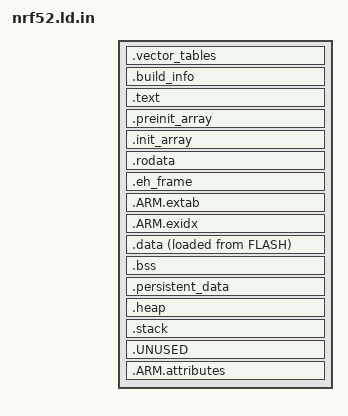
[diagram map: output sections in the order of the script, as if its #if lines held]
/*
 * Linker script for NRF52 series devices. This script is intended to be
 * pre-processed using the C preprocessor before being used.
 *
 * The following tokens must be defined:
 * MEMORY_LDI_FILE
 *
 *
 * The following preprocessor symbols may be be defined to a true or false value
 * to control the inclusion or exclusion of sections
 * KEEP_UNWIND_TABLES
 * KEEP_EXCEPTIONS
 *
 * The following symbols may be defined to a numeric value
 * HEAP_SIZE
 * MIN_STACK_SIZE
 *
 */

OUTPUT_FORMAT ("elf32-littlearm", "elf32-bigarm", "elf32-littlearm")

SEARCH_DIR(.)
GROUP(-lgcc -lc -lnosys)

INCLUDE "armv7m_vector_defaults.ldi"
INCLUDE "nrf52_vector_defaults.ldi"

/* The token MEMORY_LDI_FILE gets replaced in the preprocessing step */
INCLUDE MEMORY_LDI_FILE

SECTIONS {
    .vector_tables : {
        /* Exception and interrupt vectors */
        KEEP(*(.vector_table.armv7m*))
        KEEP(*(.vector_table.nrf52*))
    } >FLASH

    .build_info : ALIGN(4) {
        __build_info_start = .;
        KEEP(*(.build_info))
        __build_info_end = .;
    } >FLASH

    /* Normal code */
    .text : ALIGN(4) {
        *(.text*)
    } >FLASH

    /* Array of pre-initialization functions */
    .preinit_array : ALIGN(4) {
        __preinit_array_start = .;
        KEEP(*(.preinit_array))
        __preinit_array_end = .;
    } >FLASH

    /* Array of initialization functions */
    .init_array : ALIGN(4) {
        __init_array_start = .;
        KEEP(*(SORT(.init_array.*)))
        KEEP(*(.init_array))
        __init_array_end = .;
    } >FLASH

    /* Read-only data */
    .rodata : ALIGN(4) {
        *(vtable)
        *(.rodata*)
    } >FLASH

    INCLUDE "nrf5_sdk_rodata_sections.ldi"

#if KEEP_EXCEPTIONS
    /* Exception handling frame */
    .eh_frame : ALIGN(4) {
        KEEP(*(.eh_frame*))
    } >FLASH

    /* ARM exception tables */
    .ARM.extab : ALIGN(4) {
        *(.ARM.extab* .gnu.linkonce.armextab.*)
    } >FLASH
#endif

#if KEEP_UNWIND_TABLES
    /* ARM stack unwinding tables */
    .ARM.exidx : ALIGN(4) {
        __exidx_start = .;
        *(.ARM.exidx* .gnu.linkonce.armexidx.*)
        __exidx_end = .;
    } >FLASH
#endif

    .data : ALIGN(4) {
        __data_start = .;
        *(.data*)
        . = ALIGN(4);
        __data_end = .;
    } >RAM AT>FLASH

    __data_load_start = LOADADDR(.data);

    INCLUDE "nrf5_sdk_data_sections.ldi"

    .bss (NOLOAD) : ALIGN(16) {
        __bss_start = .;
        *(.bss*)
        *(COMMON)
        . = ALIGN(4);
        __bss_end = .;
    } >RAM

    .persistent_data (NOLOAD) : ALIGN(4) {
        __persistent_start = .;
        *(.persistent*)
        __persistent_end = .;
    } >RAM


#ifdef HEAP_SIZE
    .heap ALIGN(4) (NOLOAD) : {
        __heap_start = .;
        . = . + HEAP_SIZE;
        . = ALIGN(4);
        __heap_end = .;
    } >RAM
    /* Newlib uses the distinctly named 'end' symbol for the start-of-heap marker */
    PROVIDE_HIDDEN(end = __heap_start);
#endif

    /* Stack gets all the remaining RAM */
    /* There is are stack_dummy sections anywhere */
    .stack (NOLOAD) : ALIGN(4) {
        __stack_bottom = .;
        *(.stack_dummy*)
        __stack_top = ORIGIN(RAM) + LENGTH(RAM);
        __stack_size = __stack_top - __stack_bottom;
    } >RAM

#ifdef MIN_STACK_SIZE
    /* Check that stack meets or exceeds minimum size */
    ASSERT(__stack_size >= MIN_STACK_SIZE, "Stack size smaller than specified minimum");
#endif

    /* Discard unused sections explicitly */
    /DISCARD/ : {
#if !KEEP_EXCEPTIONS
        *(.eh_frame*)
        *(.ARM.extab* .gnu.linkonce.armextab.*)
#endif

#if !KEEP_UNWIND_TABLES
        *(.ARM.exidx* .gnu.linkonce.armexidx.*)
#endif
    }

    /* This could be discarded, but we keep them in the output file, just in case they do exist.
    * This let's us see what what is getting put in them (if anything)
    */
    .UNUSED (INFO) : ALIGN(4) {
        /* GCC no longer uses .init and .fini sections */
        *(.init)
        *(.fini)
        /* We never return from main, so discard global destructors */
        *(.fini_array*)
    }

    /* Keep build attributes in ELF file for analysis */
    .ARM.attributes (INFO) : ALIGN(4) {
        *(.ARM.attributes*)
    }
}
